VERSION ""

NS_ :

BS_:

BU_: IZZE_Brake_IR_4CE

BO_ 1229 IZZE_Brake_IR_4C9_Status: 8 IZZE_Brake_IR_4CE
 SG_ IZZE_Brake_IR_4C9_Internal_Temp : 7|16@0+ (0.1,-100) [0|65535] "C" Vector__XXX

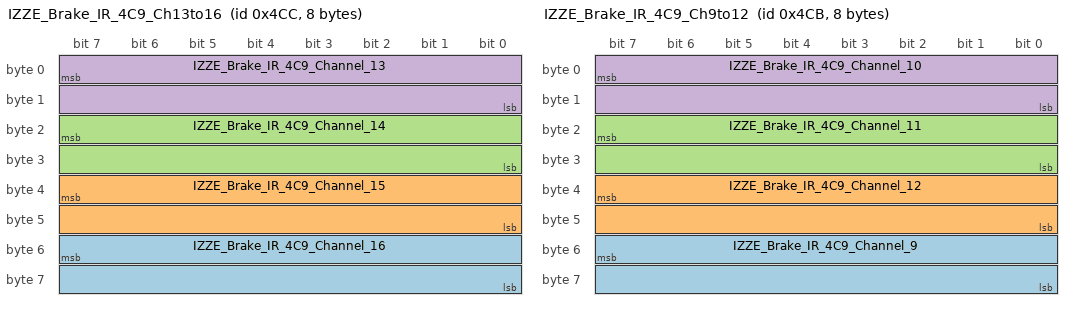
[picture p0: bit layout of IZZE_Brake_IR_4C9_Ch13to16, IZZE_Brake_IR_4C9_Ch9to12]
BO_ 1228 IZZE_Brake_IR_4C9_Ch13to16: 8 IZZE_Brake_IR_4CE
 SG_ IZZE_Brake_IR_4C9_Channel_16 : 55|16@0+ (0.1,-100) [0|65535] "C" Vector__XXX
 SG_ IZZE_Brake_IR_4C9_Channel_15 : 39|16@0+ (0.1,-100) [0|65535] "C" Vector__XXX
 SG_ IZZE_Brake_IR_4C9_Channel_14 : 23|16@0+ (0.1,-100) [0|65535] "C" Vector__XXX
 SG_ IZZE_Brake_IR_4C9_Channel_13 : 7|16@0+ (0.1,-100) [0|65535] "C" Vector__XXX

BO_ 1227 IZZE_Brake_IR_4C9_Ch9to12: 8 IZZE_Brake_IR_4CE
 SG_ IZZE_Brake_IR_4C9_Channel_9 : 55|16@0+ (0.1,-100) [0|65535] "C" Vector__XXX
 SG_ IZZE_Brake_IR_4C9_Channel_12 : 39|16@0+ (0.1,-100) [0|65535] "C" Vector__XXX
 SG_ IZZE_Brake_IR_4C9_Channel_11 : 23|16@0+ (0.1,-100) [0|65535] "C" Vector__XXX
 SG_ IZZE_Brake_IR_4C9_Channel_10 : 7|16@0+ (0.1,-100) [0|65535] "C" Vector__XXX

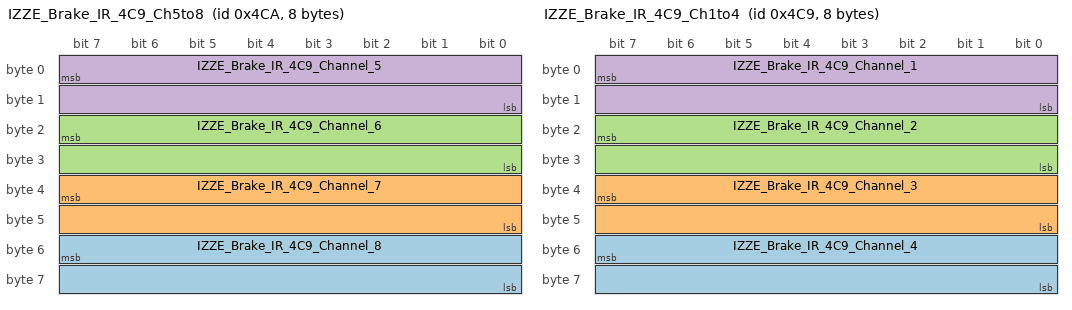
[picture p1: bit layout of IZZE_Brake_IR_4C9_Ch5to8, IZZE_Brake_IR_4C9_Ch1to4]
BO_ 1226 IZZE_Brake_IR_4C9_Ch5to8: 8 IZZE_Brake_IR_4CE
 SG_ IZZE_Brake_IR_4C9_Channel_8 : 55|16@0+ (0.1,-100) [0|65535] "C" Vector__XXX
 SG_ IZZE_Brake_IR_4C9_Channel_7 : 39|16@0+ (0.1,-100) [0|65535] "C" Vector__XXX
 SG_ IZZE_Brake_IR_4C9_Channel_6 : 23|16@0+ (0.1,-100) [0|65535] "C" Vector__XXX
 SG_ IZZE_Brake_IR_4C9_Channel_5 : 7|16@0+ (0.1,-100) [0|65535] "C" Vector__XXX

BO_ 1225 IZZE_Brake_IR_4C9_Ch1to4: 8 IZZE_Brake_IR_4CE
 SG_ IZZE_Brake_IR_4C9_Channel_4 : 55|16@0+ (0.1,-100) [0|65535] "C" Vector__XXX
 SG_ IZZE_Brake_IR_4C9_Channel_3 : 39|16@0+ (0.1,-100) [0|65535] "C" Vector__XXX
 SG_ IZZE_Brake_IR_4C9_Channel_2 : 23|16@0+ (0.1,-100) [0|65535] "C" Vector__XXX
 SG_ IZZE_Brake_IR_4C9_Channel_1 : 7|16@0+ (0.1,-100) [0|65535] "C" Vector__XXX

CM_ BO_ 1229 "Brake IR channels 13-16";
CM_ BO_ 1228 "Brake IR channels 13-16";
CM_ BO_ 1227 "Brake IR channels 9-12";
CM_ BO_ 1226 "Brake IR channels 5-8";
CM_ BO_ 1225 "Brake IR channels 1-4";
BA_DEF_  "BusType" STRING ;
BA_DEF_DEF_  "BusType" "";
BA_ "BusType" "CAN";
